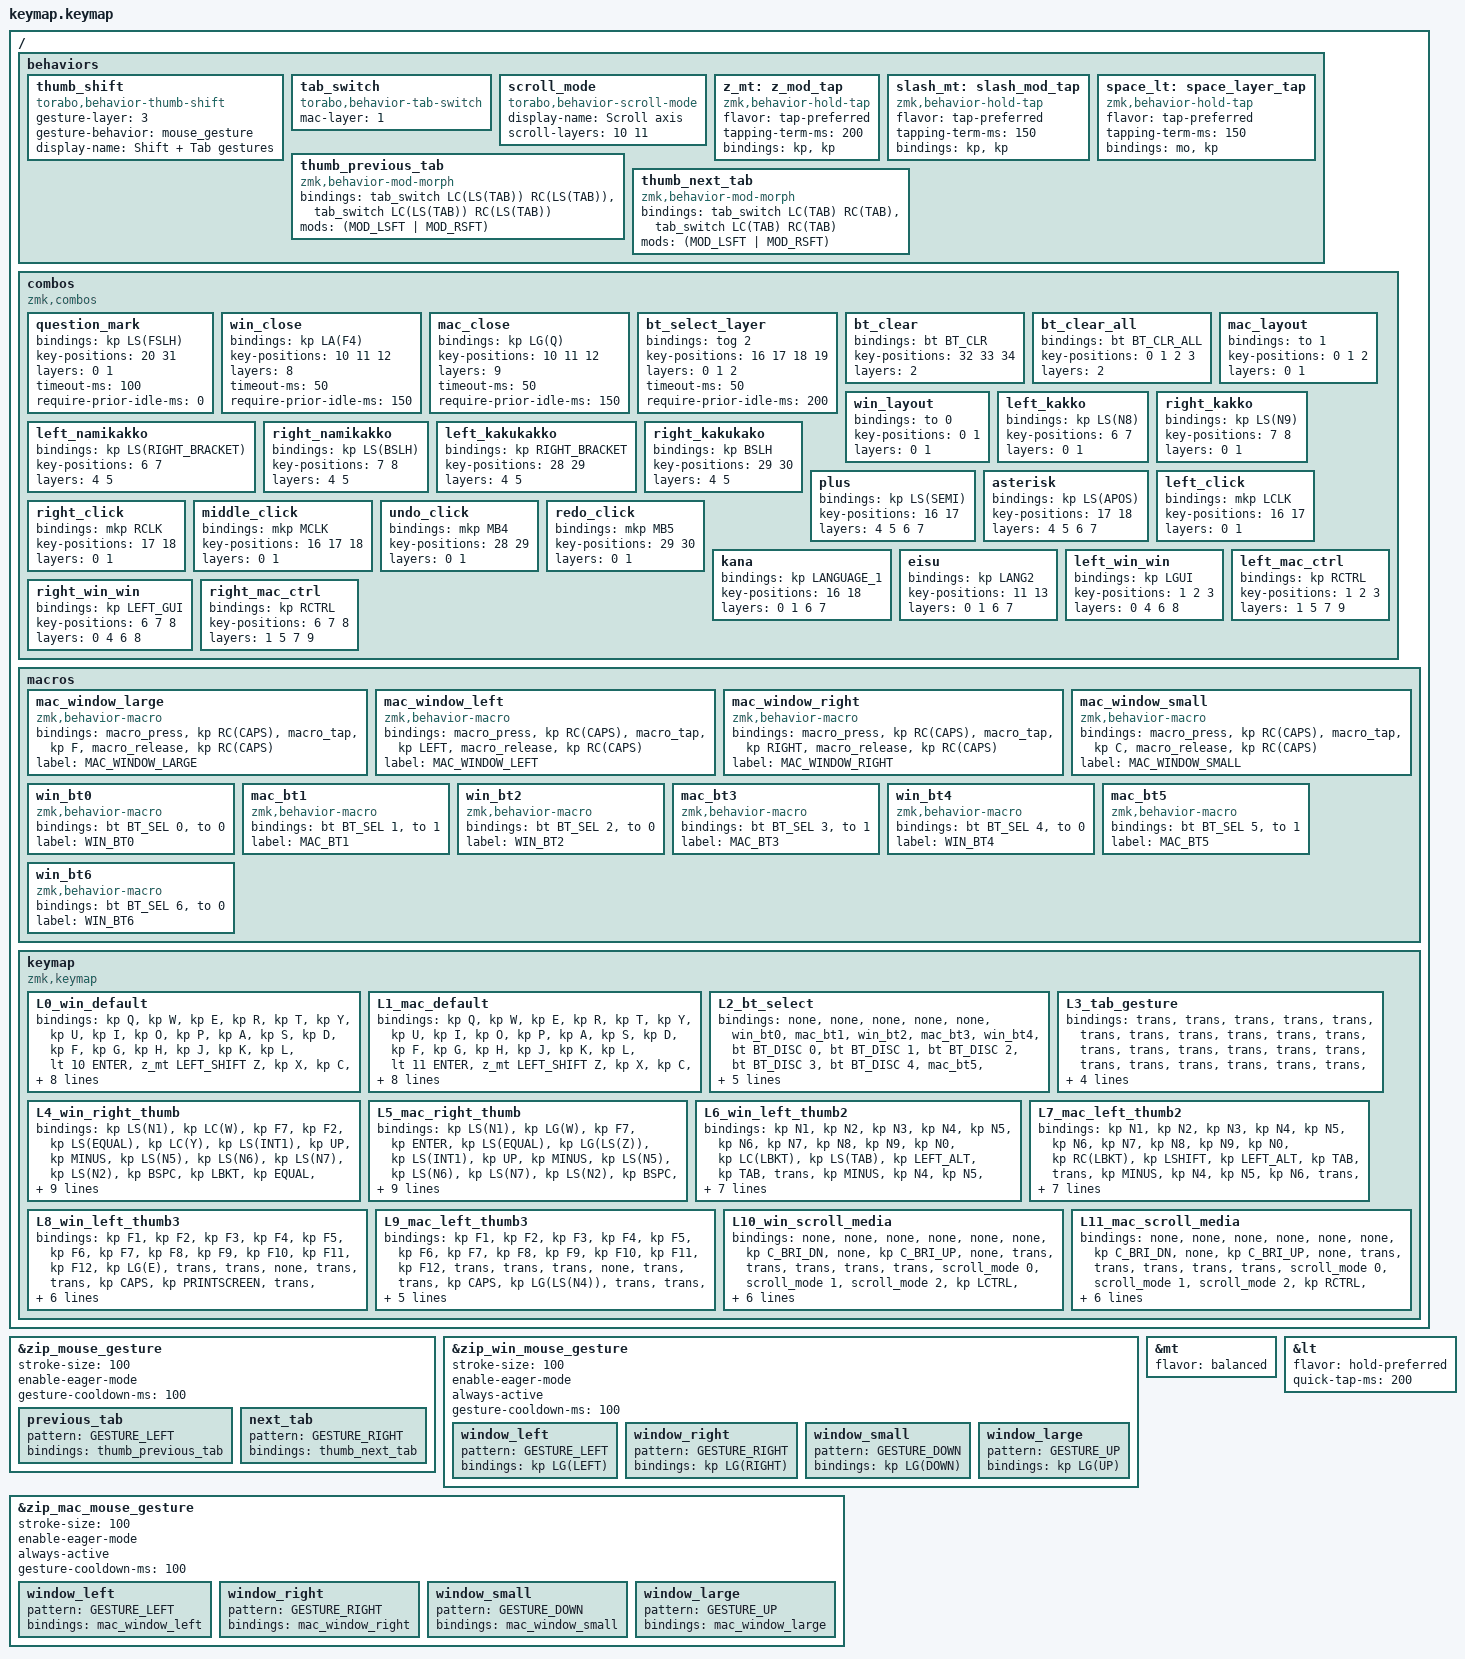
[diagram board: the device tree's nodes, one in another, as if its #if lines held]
#include <mouse-gesture.dtsi>
#include <zephyr/dt-bindings/input/input-event-codes.h>
#include <behaviors.dtsi>
#include <dt-bindings/zmk/bt.h>
#include <dt-bindings/zmk/keys.h>
#include <dt-bindings/zmk/pointing.h>

#if defined(TORABO_TSUKI_LP_INPUT_HIRES_DIAL)
#include <behaviors/hires_dial.dtsi>
#endif

#define FUNC         0x36  // Function

/ {
    behaviors {
        thumb_shift: thumb_shift {
            compatible = "torabo,behavior-thumb-shift";
            #binding-cells = <0>;
            gesture-layer = <3>;
            gesture-behavior = <&mouse_gesture>;
            display-name = "Shift + Tab gestures";
        };

        tab_switch: tab_switch {
            compatible = "torabo,behavior-tab-switch";
            #binding-cells = <2>;
            mac-layer = <1>;
        };

        scroll_mode: scroll_mode {
            compatible = "torabo,behavior-scroll-mode";
            #binding-cells = <1>;
            display-name = "Scroll axis";
            scroll-layers = <10 11>;
        };

        z_mt: z_mod_tap {
            compatible = "zmk,behavior-hold-tap";
            #binding-cells = <2>;
            flavor = "tap-preferred";
            tapping-term-ms = <200>;
            bindings = <&kp>, <&kp>;
        };

        slash_mt: slash_mod_tap {
            compatible = "zmk,behavior-hold-tap";
            #binding-cells = <2>;
            flavor = "tap-preferred";
            tapping-term-ms = <150>;
            bindings = <&kp>, <&kp>;
        };

        space_lt: space_layer_tap {
            compatible = "zmk,behavior-hold-tap";
            #binding-cells = <2>;
            flavor = "tap-preferred";
            tapping-term-ms = <150>;
            bindings = <&mo>, <&kp>;
        };

        // Mask held Shift for tab shortcuts so right still means next tab.
        thumb_previous_tab: thumb_previous_tab {
            compatible = "zmk,behavior-mod-morph";
            #binding-cells = <0>;
            bindings = <&tab_switch LC(LS(TAB)) RC(LS(TAB))>,
                       <&tab_switch LC(LS(TAB)) RC(LS(TAB))>;
            mods = <(MOD_LSFT | MOD_RSFT)>;
        };

        thumb_next_tab: thumb_next_tab {
            compatible = "zmk,behavior-mod-morph";
            #binding-cells = <0>;
            bindings = <&tab_switch LC(TAB) RC(TAB)>,
                       <&tab_switch LC(TAB) RC(TAB)>;
            mods = <(MOD_LSFT | MOD_RSFT)>;
        };
    };

    combos {
        compatible = "zmk,combos";

        question_mark {
            bindings = <&kp LS(FSLH)>;
            key-positions = <20 31>;
            layers = <0 1>;
            timeout-ms = <100>;
            // Allow the combo during typing; keep the normal Z hold-tap unchanged.
            require-prior-idle-ms = <0>;
        };

        win_close {
            bindings = <&kp LA(F4)>;
            key-positions = <10 11 12>;
            layers = <8>;
            timeout-ms = <50>;
            require-prior-idle-ms = <150>;
        };

        mac_close {
            bindings = <&kp LG(Q)>;
            key-positions = <10 11 12>;
            layers = <9>;
            timeout-ms = <50>;
            require-prior-idle-ms = <150>;
        };

        bt_select_layer {
            bindings = <&tog 2>;
            key-positions = <16 17 18 19>;
            layers = <0 1 2>;
            timeout-ms = <50>;
            require-prior-idle-ms = <200>;
        };

        bt_clear {
            bindings = <&bt BT_CLR>;
            key-positions = <32 33 34>;
            layers = <2>;
        };

        bt_clear_all {
            bindings = <&bt BT_CLR_ALL>;
            key-positions = <0 1 2 3>;
            layers = <2>;
        };

        mac_layout {
            bindings = <&to 1>;
            key-positions = <0 1 2>;
            layers = <0 1>;
        };

        win_layout {
            bindings = <&to 0>;
            key-positions = <0 1>;
            layers = <0 1>;
        };

        left_kakko {
            bindings = <&kp LS(N8)>;
            key-positions = <6 7>;
            layers = <0 1>;
        };

        right_kakko {
            bindings = <&kp LS(N9)>;
            key-positions = <7 8>;
            layers = <0 1>;
        };

        left_namikakko {
            bindings = <&kp LS(RIGHT_BRACKET)>;
            key-positions = <6 7>;
            layers = <4 5>;
        };

        right_namikakko {
            bindings = <&kp LS(BSLH)>;
            key-positions = <7 8>;
            layers = <4 5>;
        };

        left_kakukakko {
            bindings = <&kp RIGHT_BRACKET>;
            key-positions = <28 29>;
            layers = <4 5>;
        };

        right_kakukako {
            bindings = <&kp BSLH>;
            key-positions = <29 30>;
            layers = <4 5>;
        };

        //        semicolon {
        //            bindings = <&kp SEMI>;
        //            key-positions = <16 17>;
        //            layers = <10 11>;
        //        };
        //
        //        colon {
        //            bindings = <&kp APOS>;
        //            key-positions = <17 18>;
        //            layers = <10 11>;
        //        };

        plus {
            bindings = <&kp LS(SEMI)>;
            key-positions = <16 17>;
            layers = <4 5 6 7>;
        };

        asterisk {
            bindings = <&kp LS(APOS)>;
            key-positions = <17 18>;
            layers = <4 5 6 7>;
        };

        left_click {
            bindings = <&mkp LCLK>;
            key-positions = <16 17>;
            layers = <0 1>;
        };

        right_click {
            bindings = <&mkp RCLK>;
            key-positions = <17 18>;
            layers = <0 1>;
        };

        middle_click {
            bindings = <&mkp MCLK>;
            key-positions = <16 17 18>;
            layers = <0 1>;
        };

        undo_click {
            bindings = <&mkp MB4>;
            key-positions = <28 29>;
            layers = <0 1>;
        };

        redo_click {
            bindings = <&mkp MB5>;
            key-positions = <29 30>;
            layers = <0 1>;
        };

        kana {
            bindings = <&kp LANGUAGE_1>;
            key-positions = <16 18>;
            layers = <0 1 6 7>;
        };

        eisu {
            bindings = <&kp LANG2>;
            key-positions = <11 13>;
            layers = <0 1 6 7>;
        };

        left_win_win {
            bindings = <&kp LGUI>;
            key-positions = <1 2 3>;
            layers = <0 4 6 8>;
        };

        left_mac_ctrl {
            bindings = <&kp RCTRL>;
            key-positions = <1 2 3>;
            layers = <1 5 7 9>;
        };

        right_win_win {
            bindings = <&kp LEFT_GUI>;
            key-positions = <6 7 8>;
            layers = <0 4 6 8>;
        };

        right_mac_ctrl {
            bindings = <&kp RCTRL>;
            key-positions = <6 7 8>;
            layers = <1 5 7 9>;
        };
    };

    macros {
        mac_window_large: mac_window_large {
            compatible = "zmk,behavior-macro";
            #binding-cells = <0>;
            bindings =
                <&macro_press>,
                <&kp RC(CAPS)>,
                <&macro_tap>,
                <&kp F>,
                <&macro_release>,
                <&kp RC(CAPS)>;

            label = "MAC_WINDOW_LARGE";
        };

        mac_window_left: mac_window_left {
            compatible = "zmk,behavior-macro";
            #binding-cells = <0>;
            bindings =
                <&macro_press>,
                <&kp RC(CAPS)>,
                <&macro_tap>,
                <&kp LEFT>,
                <&macro_release>,
                <&kp RC(CAPS)>;

            label = "MAC_WINDOW_LEFT";
        };

        mac_window_right: mac_window_right {
            compatible = "zmk,behavior-macro";
            #binding-cells = <0>;
            bindings =
                <&macro_press>,
                <&kp RC(CAPS)>,
                <&macro_tap>,
                <&kp RIGHT>,
                <&macro_release>,
                <&kp RC(CAPS)>;

            label = "MAC_WINDOW_RIGHT";
        };

        mac_window_small: mac_window_small {
            compatible = "zmk,behavior-macro";
            #binding-cells = <0>;
            bindings =
                <&macro_press>,
                <&kp RC(CAPS)>,
                <&macro_tap>,
                <&kp C>,
                <&macro_release>,
                <&kp RC(CAPS)>;

            label = "MAC_WINDOW_SMALL";
        };

        win_bt0: win_bt0 {
            compatible = "zmk,behavior-macro";
            #binding-cells = <0>;
            bindings = <&bt BT_SEL 0 &to 0>;
            label = "WIN_BT0";
        };

        mac_bt1: mac_bt1 {
            compatible = "zmk,behavior-macro";
            #binding-cells = <0>;
            bindings = <&bt BT_SEL 1 &to 1>;
            label = "MAC_BT1";
        };

        win_bt2: win_bt2 {
            compatible = "zmk,behavior-macro";
            #binding-cells = <0>;
            bindings = <&bt BT_SEL 2 &to 0>;
            label = "WIN_BT2";
        };

        mac_bt3: mac_bt3 {
            compatible = "zmk,behavior-macro";
            #binding-cells = <0>;
            bindings = <&bt BT_SEL 3 &to 1>;
            label = "MAC_BT3";
        };

        win_bt4: win_bt4 {
            compatible = "zmk,behavior-macro";
            #binding-cells = <0>;
            bindings = <&bt BT_SEL 4 &to 0>;
            label = "WIN_BT4";
        };

        mac_bt5: mac_bt5 {
            compatible = "zmk,behavior-macro";
            #binding-cells = <0>;
            bindings = <&bt BT_SEL 5 &to 1>;
            label = "MAC_BT5";
        };

        win_bt6: win_bt6 {
            compatible = "zmk,behavior-macro";
            #binding-cells = <0>;
            bindings = <&bt BT_SEL 6 &to 0>;
            label = "WIN_BT6";
        };
    };

    // 42 keys: S layout minus the two bottom-right trackball positions.
    keymap {
        compatible = "zmk,keymap";

        L0_win_default {
            bindings = <
&kp Q                      &kp W                      &kp E                      &kp R                      &kp T                          &kp Y                      &kp U                      &kp I                      &kp O                      &kp P
&kp A                      &kp S                      &kp D                      &kp F                      &kp G                          &kp H                      &kp J                      &kp K                      &kp L                      &lt 10 ENTER
&z_mt LEFT_SHIFT Z         &kp X                      &kp C                      &kp V                      &kp B                      &kp ESC                        &kp DELETE                 &kp N                      &kp M                      &kp COMMA                  &kp DOT                    &slash_mt RIGHT_SHIFT FSLH
&kp LCTRL                  &kp LGUI                   &kp LALT                   &thumb_shift               &space_lt 6 SPACE          &lt 8 GRAVE                    &mt RCTRL TAB              &lt 4 BSPC                                                                       &kp HOME                   &kp END
#if defined(TORABO_TSUKI_LP_KSCAN_4_DIRECTION_SWITCH)
&msc SCRL_UP &msc SCRL_DOWN &msc SCRL_LEFT &msc SCRL_RIGHT &mkp MCLK
#elif defined(TORABO_TSUKI_LP_INPUT_HIRES_DIAL)
&mkp MCLK
#endif
            >;
        };

        L1_mac_default {
            bindings = <
&kp Q                      &kp W                      &kp E                      &kp R                      &kp T                          &kp Y                      &kp U                      &kp I                      &kp O                      &kp P
&kp A                      &kp S                      &kp D                      &kp F                      &kp G                          &kp H                      &kp J                      &kp K                      &kp L                      &lt 11 ENTER
&z_mt LEFT_SHIFT Z         &kp X                      &kp C                      &kp V                      &kp B                      &kp ESC                        &kp LG(BSPC)               &kp N                      &kp M                      &kp COMMA                  &kp DOT                    &slash_mt RIGHT_SHIFT FSLH
&kp LGUI                   &kp LALT                   &kp RIGHT_CONTROL          &thumb_shift               &space_lt 7 SPACE          &lt 9 LCTRL                    &mt LEFT_GUI TAB           &lt 5 BSPC                                                                       &kp LG(LEFT)               &kp LG(RIGHT)
#if defined(TORABO_TSUKI_LP_KSCAN_4_DIRECTION_SWITCH)
&msc SCRL_UP &msc SCRL_DOWN &msc SCRL_LEFT &msc SCRL_RIGHT &mkp MCLK
#elif defined(TORABO_TSUKI_LP_INPUT_HIRES_DIAL)
&mkp MCLK
#endif
            >;
        };

        // Latched Bluetooth management: selection returns, disconnect/clear stay here.
        // No transparent bindings: unrelated keys cannot type or click here.
        L2_bt_select {
            bindings = <
&none                      &none                      &none                      &none                      &none                          &win_bt0                   &mac_bt1                   &win_bt2                   &mac_bt3                   &win_bt4
&bt BT_DISC 0              &bt BT_DISC 1              &bt BT_DISC 2              &bt BT_DISC 3              &bt BT_DISC 4                  &mac_bt5                   &win_bt6                   &none                      &none                      &tog 2
&bt BT_DISC 5              &bt BT_DISC 6              &none                      &none                      &none                      &tog 2                         &none                      &none                      &none                      &none                      &none                      &none
&none                      &none                      &none                      &studio_unlock             &none                      &none                          &none                      &none                                                                            &none                      &none
#if defined(TORABO_TSUKI_LP_KSCAN_4_DIRECTION_SWITCH)
&none &none &none &none &none
#elif defined(TORABO_TSUKI_LP_INPUT_HIRES_DIAL)
&none
#endif
            >;
        };

        // Thumb hold enables tab gestures; typing inherits the active OS/layers.
        L3_tab_gesture {
            bindings = <
&trans                     &trans                     &trans                     &trans                     &trans                         &trans                     &trans                     &trans                     &trans                     &trans
&trans                     &trans                     &trans                     &trans                     &trans                         &trans                     &trans                     &trans                     &trans                     &trans
&trans                     &trans                     &trans                     &trans                     &trans                     &trans                         &trans                     &trans                     &trans                     &trans                     &trans                     &trans
&trans                     &trans                     &trans                     &trans                     &trans                     &trans                         &trans                     &trans                                                                           &trans                     &trans
#if defined(TORABO_TSUKI_LP_KSCAN_4_DIRECTION_SWITCH)
&trans &trans &trans &trans &trans
#elif defined(TORABO_TSUKI_LP_INPUT_HIRES_DIAL)
&trans
#endif
            >;
        };

        L4_win_right_thumb {
            bindings = <
&kp LS(N1)                 &kp LC(W)                  &kp F7                     &kp F2                     &kp LS(EQUAL)                  &kp LC(Y)                  &kp LS(INT1)               &kp UP                     &kp MINUS                  &kp LS(N5)
&kp LS(N6)                 &kp LS(N7)                 &kp LS(N2)                 &kp BSPC                   &kp LBKT                       &kp EQUAL                  &kp LEFT                   &kp DOWN                   &kp RIGHT                  &kp F10
&mt LEFT_SHIFT LC(Z)       &kp LC(X)                  &kp LC(C)                  &kp LC(V)                  &kp INT3                   &kp RIGHT_BRACKET              &kp BSLH                   &kp LS(N3)                 &kp LS(N4)                 &kp SEMI                   &kp APOS                   &kp RIGHT_SHIFT
&trans                     &trans                     &trans                     &trans                     &kp LS(SPACE)              &trans                         &trans                     &trans                                                                           &trans                     &trans
#if defined(TORABO_TSUKI_LP_KSCAN_4_DIRECTION_SWITCH)
&msc SCRL_UP &msc SCRL_DOWN &msc SCRL_LEFT &msc SCRL_RIGHT &mkp MCLK
#elif defined(TORABO_TSUKI_LP_INPUT_HIRES_DIAL)
&mkp MCLK
#endif
            >;
        };

        L5_mac_right_thumb {
            bindings = <
&kp LS(N1)                 &kp LG(W)                  &kp F7                     &kp ENTER                  &kp LS(EQUAL)                  &kp LG(LS(Z))              &kp LS(INT1)               &kp UP                     &kp MINUS                  &kp LS(N5)
&kp LS(N6)                 &kp LS(N7)                 &kp LS(N2)                 &kp BSPC                   &kp LBKT                       &kp EQUAL                  &kp LEFT                   &kp DOWN                   &kp RIGHT                  &kp F10
&mt LEFT_SHIFT LG(Z)       &kp LG(X)                  &kp LG(C)                  &kp LG(V)                  &kp INT3                   &kp RIGHT_BRACKET              &kp BSLH                   &kp LS(N3)                 &kp LS(N4)                 &kp SEMI                   &kp APOS                   &kp RIGHT_SHIFT
&trans                     &trans                     &trans                     &trans                     &kp LS(SPACE)              &trans                         &trans                     &trans                                                                           &trans                     &trans
#if defined(TORABO_TSUKI_LP_KSCAN_4_DIRECTION_SWITCH)
&msc SCRL_UP &msc SCRL_DOWN &msc SCRL_LEFT &msc SCRL_RIGHT &mkp MCLK
#elif defined(TORABO_TSUKI_LP_INPUT_HIRES_DIAL)
&mkp MCLK
#endif
            >;
        };

        L6_win_left_thumb2 {
            bindings = <
&kp N1                     &kp N2                     &kp N3                     &kp N4                     &kp N5                         &kp N6                     &kp N7                     &kp N8                     &kp N9                     &kp N0
&kp LC(LBKT)               &kp LS(TAB)                &kp LEFT_ALT               &kp TAB                    &trans                         &kp MINUS                  &kp N4                     &kp N5                     &kp N6                     &trans
&trans                     &kp LG(LC(LEFT))           &kp LG(TAB)                &kp LG(LC(RIGHT))          &trans                     &trans                         &kp PERIOD                 &kp LS(SEMICOLON)          &kp N1                     &kp N2                     &kp N3                     &kp SLASH
&trans                     &trans                     &trans                     &trans                     &trans                     &trans                         &trans                     &trans                                                                           &kp N0                     &kp LS(APOS)
#if defined(TORABO_TSUKI_LP_KSCAN_4_DIRECTION_SWITCH)
&msc SCRL_UP &msc SCRL_DOWN &msc SCRL_LEFT &msc SCRL_RIGHT &mkp MCLK
#elif defined(TORABO_TSUKI_LP_INPUT_HIRES_DIAL)
&mkp MCLK
#endif
            >;
        };

        L7_mac_left_thumb2 {
            bindings = <
&kp N1                     &kp N2                     &kp N3                     &kp N4                     &kp N5                         &kp N6                     &kp N7                     &kp N8                     &kp N9                     &kp N0
&kp RC(LBKT)               &kp LSHIFT                 &kp LEFT_ALT               &kp TAB                    &trans                         &kp MINUS                  &kp N4                     &kp N5                     &kp N6                     &trans
&trans                     &kp RC(LEFT)               &kp RC(UP)                 &kp RC(RIGHT)              &trans                     &trans                         &kp PERIOD                 &kp LS(SEMICOLON)          &kp N1                     &kp N2                     &kp N3                     &kp SLASH
&trans                     &trans                     &trans                     &trans                     &trans                     &trans                         &trans                     &trans                                                                           &kp N0                     &kp LS(APOS)
#if defined(TORABO_TSUKI_LP_KSCAN_4_DIRECTION_SWITCH)
&msc SCRL_UP &msc SCRL_DOWN &msc SCRL_LEFT &msc SCRL_RIGHT &mkp MCLK
#elif defined(TORABO_TSUKI_LP_INPUT_HIRES_DIAL)
&mkp MCLK
#endif
            >;
        };

        L8_win_left_thumb3 {
            bindings = <
&kp F1                     &kp F2                     &kp F3                     &kp F4                     &kp F5                         &kp F6                     &kp F7                     &kp F8                     &kp F9                     &kp F10
&kp F11                    &kp F12                    &kp LG(E)                  &trans                     &trans                         &none                      &trans                     &trans                     &kp CAPS                   &kp PRINTSCREEN
&trans                     &trans                     &trans                     &trans                     &trans                     &trans                         &trans                     &trans                     &trans                     &trans                     &trans                     &trans
&trans                     &trans                     &trans                     &trans                     &trans                     &trans                         &trans                     &trans                                                                           &trans                     &trans
#if defined(TORABO_TSUKI_LP_KSCAN_4_DIRECTION_SWITCH)
&msc SCRL_UP &msc SCRL_DOWN &msc SCRL_LEFT &msc SCRL_RIGHT &mkp MCLK
#elif defined(TORABO_TSUKI_LP_INPUT_HIRES_DIAL)
&mkp MCLK
#endif
            >;
        };

        L9_mac_left_thumb3 {
            bindings = <
&kp F1                     &kp F2                     &kp F3                     &kp F4                     &kp F5                         &kp F6                     &kp F7                     &kp F8                     &kp F9                     &kp F10
&kp F11                    &kp F12                    &trans                     &trans                     &trans                         &none                      &trans                     &trans                     &kp CAPS                   &kp LG(LS(N4))
&trans                     &trans                     &trans                     &trans                     &trans                     &trans                         &trans                     &trans                     &trans                     &trans                     &trans                     &trans
&trans                     &trans                     &trans                     &trans                     &trans                     &trans                         &trans                     &trans                                                                           &trans                     &trans
#if defined(TORABO_TSUKI_LP_KSCAN_4_DIRECTION_SWITCH)
&msc SCRL_UP &msc SCRL_DOWN &msc SCRL_LEFT &msc SCRL_RIGHT &mkp MCLK
#elif defined(TORABO_TSUKI_LP_INPUT_HIRES_DIAL)
&mkp MCLK
#endif
            >;
        };

        L10_win_scroll_media {
            bindings = <
&none                      &none                      &none                      &none                      &none                          &none                      &kp C_BRI_DN               &none                      &kp C_BRI_UP               &none
&trans                     &trans                     &trans                     &trans                     &trans                         &scroll_mode 0             &scroll_mode 1             &scroll_mode 2             &kp LCTRL                  &trans
&trans                     &trans                     &trans                     &trans                     &trans                     &trans                         &trans                     &trans                     &kp C_VOL_DN               &kp C_MUTE                 &kp C_VOL_UP               &trans
&trans                     &trans                     &trans                     &trans                     &trans                     &trans                         &kp C_PLAY_PAUSE           &trans                                                                           &trans                     &trans
#if defined(TORABO_TSUKI_LP_KSCAN_4_DIRECTION_SWITCH)
&msc SCRL_UP &msc SCRL_DOWN &msc SCRL_LEFT &msc SCRL_RIGHT &mkp MCLK
#elif defined(TORABO_TSUKI_LP_INPUT_HIRES_DIAL)
&mkp MCLK
#endif
            >;
        };

        L11_mac_scroll_media {
            bindings = <
&none                      &none                      &none                      &none                      &none                          &none                      &kp C_BRI_DN               &none                      &kp C_BRI_UP               &none
&trans                     &trans                     &trans                     &trans                     &trans                         &scroll_mode 0             &scroll_mode 1             &scroll_mode 2             &kp RCTRL                  &trans
&trans                     &trans                     &trans                     &trans                     &trans                     &trans                         &trans                     &trans                     &kp C_VOL_DN               &kp C_MUTE                 &kp C_VOL_UP               &trans
&trans                     &trans                     &trans                     &trans                     &trans                     &trans                         &kp C_PLAY_PAUSE           &trans                                                                           &trans                     &trans
#if defined(TORABO_TSUKI_LP_KSCAN_4_DIRECTION_SWITCH)
&msc SCRL_UP &msc SCRL_DOWN &msc SCRL_LEFT &msc SCRL_RIGHT &mkp MCLK
#elif defined(TORABO_TSUKI_LP_INPUT_HIRES_DIAL)
&mkp MCLK
#endif
            >;
        };
    };
};

&zip_mouse_gesture {
    stroke-size = <100>;
    enable-eager-mode;
    // Activation via thumb_shift resets partial strokes between holds.
    gesture-cooldown-ms = <100>;

    previous_tab {
        pattern = <GESTURE_LEFT>;
        bindings = <&thumb_previous_tab>;
    };

    next_tab {
        pattern = <GESTURE_RIGHT>;
        bindings = <&thumb_next_tab>;
    };
};

&zip_win_mouse_gesture {
    stroke-size = <100>;
    enable-eager-mode;
    always-active;
    gesture-cooldown-ms = <100>;

    window_left {
        pattern = <GESTURE_LEFT>;
        bindings = <&kp LG(LEFT)>;
    };

    window_right {
        pattern = <GESTURE_RIGHT>;
        bindings = <&kp LG(RIGHT)>;
    };

    window_small {
        pattern = <GESTURE_DOWN>;
        bindings = <&kp LG(DOWN)>;
    };

    window_large {
        pattern = <GESTURE_UP>;
        bindings = <&kp LG(UP)>;
    };
};

&zip_mac_mouse_gesture {
    stroke-size = <100>;
    enable-eager-mode;
    always-active;
    gesture-cooldown-ms = <100>;

    window_left {
        pattern = <GESTURE_LEFT>;
        bindings = <&mac_window_left>;
    };

    window_right {
        pattern = <GESTURE_RIGHT>;
        bindings = <&mac_window_right>;
    };

    window_small {
        pattern = <GESTURE_DOWN>;
        bindings = <&mac_window_small>;
    };

    window_large {
        pattern = <GESTURE_UP>;
        bindings = <&mac_window_large>;
    };
};

&mt { flavor = "balanced"; };

&lt {
    flavor = "hold-preferred";
    quick-tap-ms = <200>;
};

#if defined(TORABO_TSUKI_LP_INPUT_HIRES_DIAL)
&{/keymap/L0_win_default} {
    sensor-bindings = <&hires_dial_scroll 1 1>;
};

&{/keymap/L1_mac_default} {
    sensor-bindings = <&hires_dial_scroll 10 1>;
};

#endif
